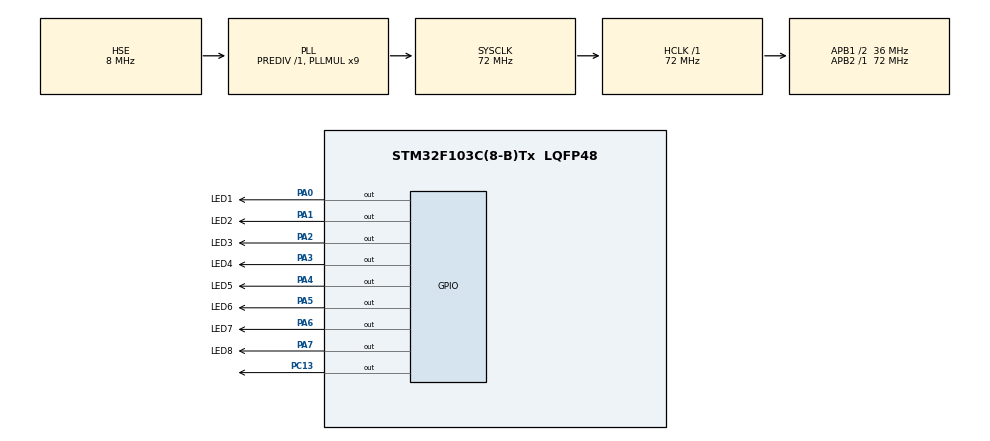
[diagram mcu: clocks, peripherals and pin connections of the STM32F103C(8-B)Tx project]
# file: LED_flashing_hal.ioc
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Mcu.Family=STM32F1
Mcu.Name=STM32F103C(8-B)Tx
Mcu.Package=LQFP48
NVIC.PriorityGroup=NVIC_PRIORITYGROUP_4
PA0-WKUP.GPIO_Label=LED1
PA0-WKUP.GPIO_PuPd=GPIO_PULLUP
PA0-WKUP.GPIO_Speed=GPIO_SPEED_FREQ_HIGH
PA0-WKUP.Signal=GPIO_Output
PA1.GPIO_Label=LED2
PA1.GPIO_PuPd=GPIO_PULLUP
PA1.GPIO_Speed=GPIO_SPEED_FREQ_HIGH
PA1.Signal=GPIO_Output
PA13.Mode=Serial_Wire
PA13.Signal=SYS_JTMS-SWDIO
PA14.Mode=Serial_Wire
PA14.Signal=SYS_JTCK-SWCLK
PA2.GPIO_Label=LED3
PA2.GPIO_PuPd=GPIO_PULLUP
PA2.GPIO_Speed=GPIO_SPEED_FREQ_HIGH
PA2.Signal=GPIO_Output
PA3.GPIO_Label=LED4
PA3.GPIO_PuPd=GPIO_PULLUP
PA3.GPIO_Speed=GPIO_SPEED_FREQ_HIGH
PA3.Signal=GPIO_Output
PA4.GPIO_Label=LED5
PA4.GPIO_PuPd=GPIO_PULLUP
PA4.GPIO_Speed=GPIO_SPEED_FREQ_HIGH
PA4.Signal=GPIO_Output
PA5.GPIO_Label=LED6
PA5.GPIO_PuPd=GPIO_PULLUP
PA5.GPIO_Speed=GPIO_SPEED_FREQ_HIGH
PA5.Signal=GPIO_Output
PA6.GPIO_Label=LED7
PA6.GPIO_PuPd=GPIO_PULLUP
PA6.GPIO_Speed=GPIO_SPEED_FREQ_HIGH
PA6.Signal=GPIO_Output
PA7.GPIO_Label=LED8
PA7.GPIO_PuPd=GPIO_PULLUP
PA7.GPIO_Speed=GPIO_SPEED_FREQ_HIGH
PA7.Signal=GPIO_Output
PC13-TAMPER-RTC.GPIO_Speed=GPIO_SPEED_FREQ_HIGH
PC13-TAMPER-RTC.Signal=GPIO_Output
PC14-OSC32_IN.Mode=LSE-External-Oscillator
PC14-OSC32_IN.Signal=RCC_OSC32_IN
PC15-OSC32_OUT.Mode=LSE-External-Oscillator
PC15-OSC32_OUT.Signal=RCC_OSC32_OUT
PD0-OSC_IN.Mode=HSE-External-Oscillator
PD0-OSC_IN.Signal=RCC_OSC_IN
PD1-OSC_OUT.Mode=HSE-External-Oscillator
PD1-OSC_OUT.Signal=RCC_OSC_OUT
ProjectManager.HeapSize=0x200
ProjectManager.StackSize=0x400
ProjectManager.TargetToolchain=MDK-ARM V5.32
RCC.AHBFreq_Value=72000000
RCC.APB1CLKDivider=RCC_HCLK_DIV2
RCC.APB1Freq_Value=36000000
RCC.APB1TimFreq_Value=72000000
RCC.APB2Freq_Value=72000000
RCC.APB2TimFreq_Value=72000000
RCC.HCLKFreq_Value=72000000
RCC.PLLMUL=RCC_PLL_MUL9
RCC.PLLSourceVirtual=RCC_PLLSOURCE_HSE
RCC.SYSCLKFreq_VALUE=72000000
RCC.SYSCLKSource=RCC_SYSCLKSOURCE_PLLCLK
RCC.USBFreq_Value=72000000
board=custom

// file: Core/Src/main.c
/* USER CODE BEGIN Header */
/**
 ******************************************************************************
 * @file           : main.c
 * @brief          : Main program body
 ******************************************************************************
 * @attention
 *
 * Copyright (c) 2025 STMicroelectronics.
 * All rights reserved.
 *
 * This software is licensed under terms that can be found in the LICENSE file
 * in the root directory of this software component.
 * If no LICENSE file comes with this software, it is provided AS-IS.
 *
 ******************************************************************************
 */
/* USER CODE END Header */
#include "main.h"
#include "gpio.h"

/* USER CODE BEGIN PV */
uint16_t led_pins[] = {LED1_Pin, LED2_Pin, LED3_Pin, LED4_Pin, LED5_Pin, LED6_Pin, LED7_Pin, LED8_Pin};
/* USER CODE END PV */

void
SystemClock_Config(void);

int main(void)
{

  /* MCU Configuration--------------------------------------------------------*/

  /* Reset of all peripherals, Initializes the Flash interface and the Systick. */
  HAL_Init();

  /* Configure the system clock */
  SystemClock_Config();

  /* Initialize all configured peripherals */
  MX_GPIO_Init();

  /* Infinite loop */
  /* USER CODE BEGIN WHILE */
  while (1)
  {
    for (uint8_t i = 0; i < 8; i++)
    {
      for (uint8_t j = 0; j < 8; j++)
      {
        HAL_GPIO_WritePin(GPIOA, led_pins[j], GPIO_PIN_SET);
      }
      HAL_GPIO_WritePin(GPIOA, led_pins[i], GPIO_PIN_RESET);
      HAL_Delay(500);
    }
    /* USER CODE END WHILE */

  }
}

void SystemClock_Config(void)
{
  RCC_OscInitTypeDef RCC_OscInitStruct = {0};
  RCC_ClkInitTypeDef RCC_ClkInitStruct = {0};

  /** Initializes the RCC Oscillators according to the specified parameters
   * in the RCC_OscInitTypeDef structure.
   */
  RCC_OscInitStruct.OscillatorType = RCC_OSCILLATORTYPE_HSE;
  RCC_OscInitStruct.HSEState = RCC_HSE_ON;
  RCC_OscInitStruct.HSEPredivValue = RCC_HSE_PREDIV_DIV1;
  RCC_OscInitStruct.HSIState = RCC_HSI_ON;
  RCC_OscInitStruct.PLL.PLLState = RCC_PLL_ON;
  RCC_OscInitStruct.PLL.PLLSource = RCC_PLLSOURCE_HSE;
  RCC_OscInitStruct.PLL.PLLMUL = RCC_PLL_MUL9;
  if (HAL_RCC_OscConfig(&RCC_OscInitStruct) != HAL_OK)
  {
    Error_Handler();
  }

  /** Initializes the CPU, AHB and APB buses clocks
   */
  RCC_ClkInitStruct.ClockType = RCC_CLOCKTYPE_HCLK | RCC_CLOCKTYPE_SYSCLK | RCC_CLOCKTYPE_PCLK1 | RCC_CLOCKTYPE_PCLK2;
  RCC_ClkInitStruct.SYSCLKSource = RCC_SYSCLKSOURCE_PLLCLK;
  RCC_ClkInitStruct.AHBCLKDivider = RCC_SYSCLK_DIV1;
  RCC_ClkInitStruct.APB1CLKDivider = RCC_HCLK_DIV2;
  RCC_ClkInitStruct.APB2CLKDivider = RCC_HCLK_DIV1;

  if (HAL_RCC_ClockConfig(&RCC_ClkInitStruct, FLASH_LATENCY_2) != HAL_OK)
  {
    Error_Handler();
  }
}

void Error_Handler(void)
{
  __disable_irq();
  while (1)
  {
  }
}
